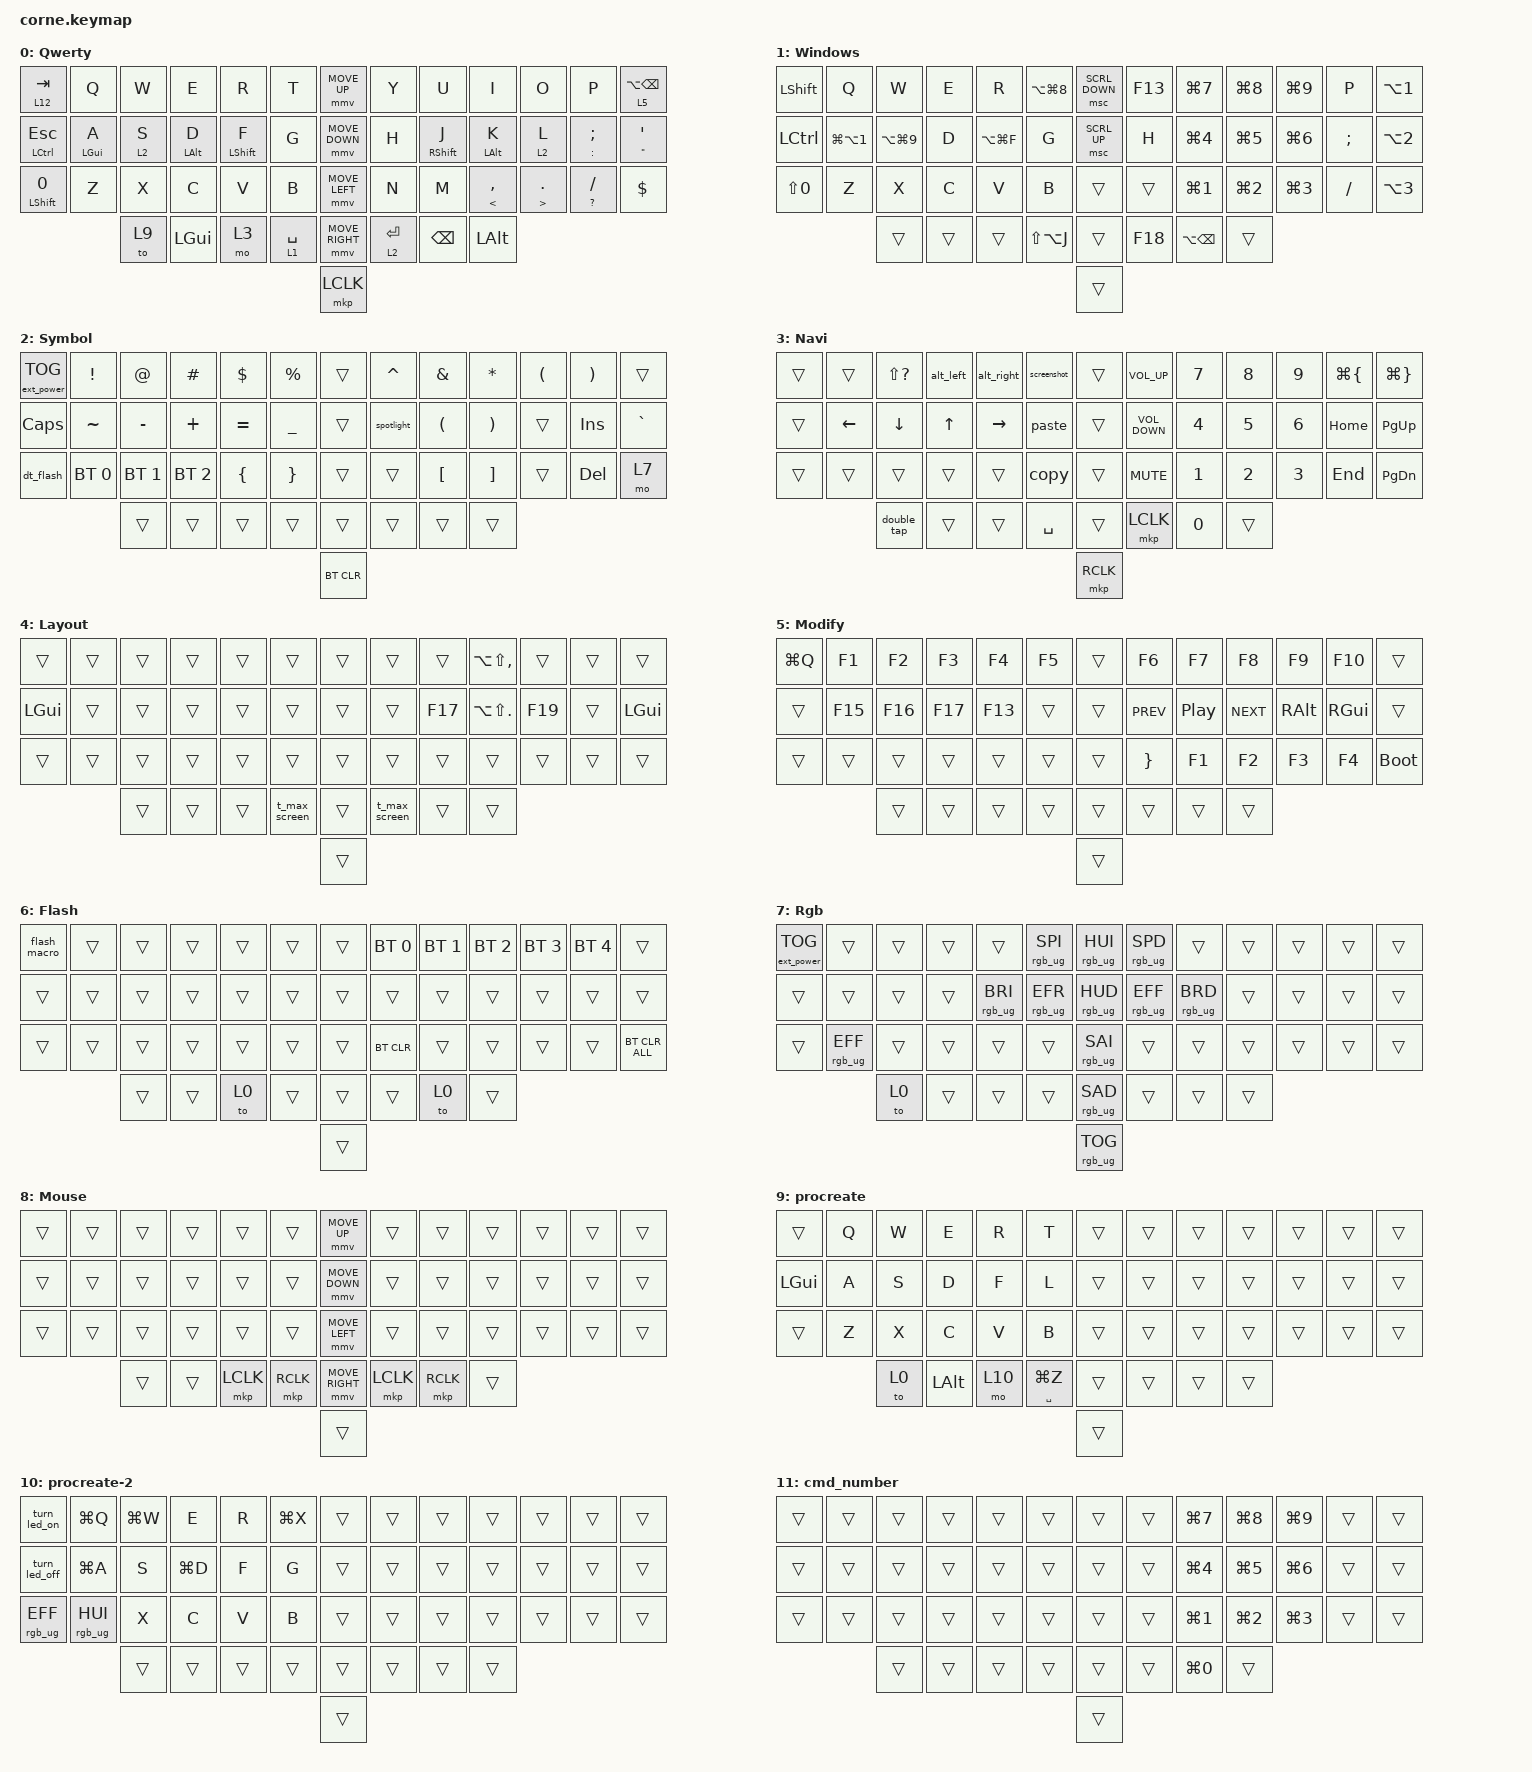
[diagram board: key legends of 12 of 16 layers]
#define ZMK_POINTING_DEFAULT_MOVE_VAL 1200  // 600
#define ZMK_POINTING_DEFAULT_SCRL_VAL 35    // 10

#include <input/processors.dtsi>
#include <zephyr/dt-bindings/input/input-event-codes.h>
#include <behaviors.dtsi>
#include <dt-bindings/zmk/bt.h>
#include <dt-bindings/zmk/ext_power.h>
#include <dt-bindings/zmk/keys.h>
#include <dt-bindings/zmk/pointing.h>
#include <dt-bindings/zmk/rgb.h>

/ {
    zip_scroll_scaler: zip_scroll_scaler {
        compatible = "zmk,input-processor-scaler";
        #input-processor-cells = <2>;
        type = <INPUT_EV_REL>;
        codes = <INPUT_REL_WHEEL INPUT_REL_HWHEEL>;
        track-remainders;
    };
};

&mmv_input_listener { input-processors = <&zip_xy_scaler 2 1>; };

&msc_input_listener { input-processors = <&zip_scroll_scaler 2 1>; };

&msc {
    acceleration-exponent = <0>;      // 0
    time-to-max-speed-ms = <0>;       // 300
    delay-ms = <0>;                   // 0
};

&mmv {
    time-to-max-speed-ms = <400>;
    acceleration-exponent = <1>;
};

/ {
    macros {
        t_max_screen: toggle_max_screen {
            compatible = "zmk,behavior-macro";
            #binding-cells = <0>;
            bindings = <&kp LG(LS(SPACE))>;
            label = "TOGGLE_MAX_SCREEN";
        };

        vim_exit: vim_exit {
            compatible = "zmk,behavior-macro";
            #binding-cells = <0>;
            bindings = <&kp ESCAPE &kp LA(C) &kp COLON>;
            label = "VIM_EXIT";
        };

        screenshot: screenshot {
            compatible = "zmk,behavior-macro";
            #binding-cells = <0>;
            bindings = <&kp LG(LS(NUMBER_4))>;
            label = "SCREENSHOT";
        };

        spotlight: spotlight {
            compatible = "zmk,behavior-macro";
            #binding-cells = <0>;
            bindings = <&kp LG(SPACE)>;
            label = "SPOTLIGHT";
        };

        alt_left: alt_left {
            compatible = "zmk,behavior-macro";
            #binding-cells = <0>;
            bindings = <&kp LA(LEFT)>;
            label = "ALT_LEFT";
        };

        alt_right: alt_right {
            compatible = "zmk,behavior-macro";
            #binding-cells = <0>;
            bindings = <&kp LA(RIGHT)>;
            label = "ALT_RIGHT";
        };

        copy: copy {
            compatible = "zmk,behavior-macro";
            #binding-cells = <0>;
            bindings = <&kp LG(C)>;
            label = "COPY";
        };

        paste: paste {
            compatible = "zmk,behavior-macro";
            #binding-cells = <0>;
            bindings = <&kp LG(V)>;
            label = "PASTE";
        };

        ctrl_right: ctrl_right {
            compatible = "zmk,behavior-macro";
            #binding-cells = <0>;
            bindings = <&kp LC(RIGHT)>;
            label = "CTRL_RIGHT";
        };

        ctrl_left: ctrl_left {
            compatible = "zmk,behavior-macro";
            #binding-cells = <0>;
            bindings = <&kp LC(LEFT)>;
            label = "CTRL_LEFT";
        };

        focus_1_screen: focus_1_screen {
            compatible = "zmk,behavior-macro";
            #binding-cells = <0>;
            bindings = <&kp LS(LA(LC(W)))>;
            label = "FOCUS_1_SCREEN";
        };

        focus_2_screen: focus_2_screen {
            compatible = "zmk,behavior-macro";
            #binding-cells = <0>;
            bindings = <&kp LS(LA(LC(E)))>;
            label = "FOCUS_2_SCREEN";
        };

        focus_3_screen: focus_3_screen {
            compatible = "zmk,behavior-macro";
            #binding-cells = <0>;
            bindings = <&kp LS(LA(LC(R)))>;
            label = "FOCUS_3_SCREEN";
        };

        throw_1_screen: throw_1_screen {
            compatible = "zmk,behavior-macro";
            #binding-cells = <0>;
            bindings = <&kp LS(LA(LC(M)))>;
            label = "THROW_1_SCREEN";
        };

        throw_2_screen: throw_2_screen {
            compatible = "zmk,behavior-macro";
            #binding-cells = <0>;
            bindings = <&kp LS(LA(LC(E)))>;
            label = "THROW_2_SCREEN";
        };

        throw_3_screen: throw_3_screen {
            compatible = "zmk,behavior-macro";
            #binding-cells = <0>;
            bindings = <&kp LS(LA(LC(R)))>;
            label = "THROW_3_SCREEN";
        };

        throw_1_space: throw_1_space {
            compatible = "zmk,behavior-macro";
            #binding-cells = <0>;
            bindings = <&kp LS(LA(LC(LG(J))))>;
            label = "THROW_1_SPACE";
        };

        throw_2_space: throw_2_space {
            compatible = "zmk,behavior-macro";
            #binding-cells = <0>;
            bindings = <&kp LS(LA(LC(LG(K))))>;
            label = "THROW_2_SPACE";
        };

        throw_3_space: throw_3_space {
            compatible = "zmk,behavior-macro";
            #binding-cells = <0>;
            bindings = <&kp LS(LA(LC(LG(L))))>;
            label = "THROW_3_SPACE";
        };

        throw_4_space: throw_4_space {
            compatible = "zmk,behavior-macro";
            #binding-cells = <0>;
            bindings = <&kp LS(LA(LC(LG(U))))>;
            label = "THROW_4_SPACE";
        };

        throw_5_space: throw_5_space {
            compatible = "zmk,behavior-macro";
            #binding-cells = <0>;
            bindings = <&kp LS(LA(LC(LG(I))))>;
            label = "THROW_5_SPACE";
        };

        throw_6_space: throw_6_space {
            compatible = "zmk,behavior-macro";
            #binding-cells = <0>;
            bindings = <&kp LS(LC(LA(LG(O))))>;
            label = "THROW_6_SPACE";
        };

        focus_space_1: focus_space_1 {
            compatible = "zmk,behavior-macro";
            #binding-cells = <0>;
            bindings = <&kp LS(LA(LC(J)))>;
            label = "FOCUS_SPACE_1";
        };

        focus_space_2: focus_space_2 {
            compatible = "zmk,behavior-macro";
            #binding-cells = <0>;
            bindings = <&kp LS(LC(LA(K)))>;
            label = "FOCUS_SPACE_2";
        };

        focus_space_3: focus_space_3 {
            compatible = "zmk,behavior-macro";
            #binding-cells = <0>;
            bindings = <&kp LS(LA(LC(L)))>;
            label = "FOCUS_SPACE_3";
        };

        focus_space_4: focus_space_4 {
            compatible = "zmk,behavior-macro";
            #binding-cells = <0>;
            bindings = <&kp LS(LA(LC(U)))>;
            label = "FOCUS_SPACE_4";
        };

        focus_space_5: focus_space_5 {
            compatible = "zmk,behavior-macro";
            #binding-cells = <0>;
            bindings = <&kp LS(LA(LC(I)))>;
            label = "FOCUS_SPACE_5";
        };

        focus_space_6: focus_space_6 {
            compatible = "zmk,behavior-macro";
            #binding-cells = <0>;
            bindings = <&kp LS(LA(LC(O)))>;
            label = "FOCUS_SPACE_6";
        };

        attach_windows: attatch_windows {
            compatible = "zmk,behavior-macro";
            #binding-cells = <0>;
            bindings = <&bt BT_SEL 3 &to 1>;
            label = "ATTATCH_WINDOWS";
        };

        attach_mac_personal: attach_mac_personal {
            compatible = "zmk,behavior-macro";
            #binding-cells = <0>;
            bindings = <&bt BT_SEL 0 &to 0>;
            label = "ATTACH_MAC_PERSONAL";
        };

        attach_mac_work: attach_mac_work {
            compatible = "zmk,behavior-macro";
            #binding-cells = <0>;
            bindings = <&bt BT_SEL 1 &to 0>;
            label = "ATTACH_MAC_WORK";
        };

        flash_macro: flash_macro {
            compatible = "zmk,behavior-macro";
            #binding-cells = <0>;
            bindings = <&bootloader>;
        };

        turn_led_on: turn_led_on {
            compatible = "zmk,behavior-macro";
            #binding-cells = <0>;
            bindings = <&ext_power EP_ON &rgb_ug RGB_ON>;
            label = "TURN_LED_ON";
        };

        turn_led_off: turn_led_off {
            compatible = "zmk,behavior-macro";
            #binding-cells = <0>;
            bindings = <&ext_power EP_OFF>;
            label = "TURN_LED_OFF";
        };

        vim_ciw: vim_ciw {
            compatible = "zmk,behavior-macro";
            #binding-cells = <0>;
            bindings = <&kp C &kp I &kp W>;
            label = "VIM_CIW";
        };
    };

    behaviors {
        hml: homerow_mods_left {
            compatible = "zmk,behavior-hold-tap";
            label = "HOMEROW_MODS_LEFT";
            bindings = <&kp>, <&kp>;

            #binding-cells = <2>;
            tapping-term-ms = <200>;
            quick-tap-ms = <180>;
            flavor = "tap-preferred";
            require-prior-idle-ms = <200>;
            hold-trigger-key-positions = <21 22 23 24>;
            hold-trigger-on-release;
            hold-while-undecided;
        };

        ltq: ltq {
            compatible = "zmk,behavior-hold-tap";
            label = "LTQ";
            bindings = <&mo>, <&kp>;

            #binding-cells = <2>;
            tapping-term-ms = <250>;
            quick-tap-ms = <150>;
            flavor = "tap-preferred";
        };

        as: auto_shift {
            compatible = "zmk,behavior-hold-tap";
            label = "AUTO_SHIFT";
            bindings = <&kp>, <&kp>;

            #binding-cells = <2>;
            tapping-term-ms = <180>;
            quick-tap-ms = <0>;
            flavor = "tap-preferred";
        };

        rgb_encoder: rgb_encoder {
            compatible = "zmk,behavior-sensor-rotate";
            label = "RGB_ENCODER";
            #sensor-binding-cells = <0>;
            bindings = <&rgb_ug RGB_BRI>, <&rgb_ug RGB_BRD>;
        };

        scroll_encoder: scroll_encoder {
            compatible = "zmk,behavior-sensor-rotate";
            #sensor-binding-cells = <0>;
            bindings = <&msc SCRL_UP>, <&msc SCRL_DOWN>;

            tap-ms = <30>;
        };

        hmr: hmr {
            compatible = "zmk,behavior-hold-tap";
            label = "HMR";
            bindings = <&kp>, <&kp>;

            #binding-cells = <2>;
            tapping-term-ms = <200>;
            quick-tap-ms = <180>;
            flavor = "tap-preferred";
            require-prior-idle-ms = <200>;
            hold-trigger-key-positions = <17 16 15 14>;
            hold-trigger-on-release;
            hold-while-undecided;
        };

        long_hold: long_hold {
            compatible = "zmk,behavior-hold-tap";
            label = "LONG_HOLD";
            bindings = <&none>, <&none>;

            #binding-cells = <2>;
            tapping-term-ms = <1000>;
            flavor = "tap-preferred";
        };

        double_tap: double_tap {
            compatible = "zmk,behavior-tap-dance";
            label = "DOUBLE_TAP";
            #binding-cells = <0>;
            bindings = <&bt BT_CLR>;
            tapping-term-ms = <200>;
        };

        dt_flash: dt_flash {
            compatible = "zmk,behavior-tap-dance";
            label = "DT_FLASH";
            #binding-cells = <0>;
            bindings = <&none>, <&to 6>;
        };

        hml_layer: hml_layer {
            compatible = "zmk,behavior-hold-tap";
            label = "HML_LAYER";
            bindings = <&mo>, <&kp>;

            #binding-cells = <2>;
            hold-trigger-key-positions = <15 23>;
            tapping-term-ms = <200>;
            quick-tap-ms = <180>;
            require-prior-idle-ms = <(-1)>;
            flavor = "tap-preferred";
        };

        quick_tap: quick_tap {
            compatible = "zmk,behavior-hold-tap";
            label = "QUICK_TAP";
            bindings = <&kp>, <&kp>;

            #binding-cells = <2>;
            tapping-term-ms = <180>;
            quick-tap-ms = <0>;
            require-prior-idle-ms = <0>;
            hold-trigger-on-release;
            hold-while-undecided;
        };
    };

    combos {
        compatible = "zmk,combos";

        combo_right_esc {
            bindings = <&mo 4>;
            key-positions = <46 38>;
            timeout-ms = <70>;
        };

        combo_left_esc {
            bindings = <&mo 4>;
            key-positions = <26 40>;
            timeout-ms = <70>;
        };

        combo_vim {
            bindings = <&vim_exit>;
            key-positions = <41 45>;
            timeout-ms = <150>;
        };

        quick_tap_esc {
            bindings = <&kp ESC>;
            key-positions = <26 40>;
            timeout-ms = <20>;
        };

        l4 {
            bindings = <&to 6>;
            key-positions = <46 40>;
        };

        backslash {
            bindings = <&kp BACKSLASH>;
            key-positions = <7 21>;
            timeout-ms = <100>;
        };

        comma {
            bindings = <&kp COMMA>;
            key-positions = <18 20>;
        };

        lock_pc {
            bindings = <&kp LG(LC(Q))>;
            key-positions = <0 42 44 12>;
            timeout-ms = <150>;
        };

        pipe {
            bindings = <&kp PIPE>;
            key-positions = <20 7>;
        };

        ctrl-c {
            bindings = <&kp LC(C)>;
            key-positions = <13 25>;
        };

        flash {
            bindings = <&to 6>;
            key-positions = <47 39>;
        };

        period_combo {
            bindings = <&kp PERIOD>;
            key-positions = <21 17>;
        };

        enter-left-hand {
            bindings = <&kp ENTER>;
            key-positions = <14 15 16 17>;
        };

        ciw {
            bindings = <&vim_ciw>;
            key-positions = <25 13>;
        };

        esc_thumb {
            bindings = <&kp ESCAPE>;
            key-positions = <42 44>;
        };

        move_window {
            bindings = <&mo 15>;
            key-positions = <46 12>;
        };

        delete {
            bindings = <&kp LA(DELETE)>;
            key-positions = <15 17>;
        };
    };

    keymap {
        compatible = "zmk,keymap";

        Qwerty {
            bindings = <
&lt 12 TAB                &kp Q            &kp W           &kp E            &kp R              &kp T           &mmv MOVE_UP     &kp Y         &kp U               &kp I                &kp O                    &kp P               &lt 5 LA(BACKSPACE)
&mt LEFT_CONTROL ESC      &hml LEFT_GUI A  &hml_layer 2 S  &hml LEFT_ALT D  &hml LEFT_SHIFT F  &kp G           &mmv MOVE_DOWN   &kp H         &hmr RIGHT_SHIFT J  &hmr LEFT_ALT K      &hml_layer 2 L           &as COLON SEMI      &as DOUBLE_QUOTES SQT
&quick_tap LEFT_SHIFT N0  &kp Z            &kp X           &kp C            &kp V              &kp B           &mmv MOVE_LEFT   &kp N         &kp M               &as LESS_THAN COMMA  &as GREATER_THAN PERIOD  &as QUESTION SLASH  &kp DOLLAR
                                           &to 9           &kp LEFT_GUI     &mo 3              &ltq 1 SPACE    &mmv MOVE_RIGHT  &ltq 2 ENTER  &kp BACKSPACE       &kp LEFT_ALT
                                                                                                               &mkp LCLK
            >;

            label = "Qwerty";
            sensor-bindings = <&inc_dec_kp C_VOLUME_UP C_VOLUME_DOWN>;
        };

        Windows {
            bindings = <
&kp LEFT_SHIFT  &kp Q                 &kp W           &kp E   &kp R          &kp LA(LG(N8))    &msc SCRL_DOWN  &kp F13  &kp LG(N7)         &kp LG(N8)        &kp LG(N9)        &kp P     &kp LA(NUMBER_1)
&kp LCTRL       &kp LG(LA(NUMBER_1))  &kp LA(LG(N9))  &kp D   &kp LA(LG(F))  &kp G             &msc SCRL_UP    &kp H    &kp LG(NUMBER_4)   &kp LG(N5)        &kp LG(NUMBER_6)  &kp SEMI  &kp LA(NUMBER_2)
&kp LS(N0)      &kp Z                 &kp X           &kp C   &kp V          &kp B             &trans          &trans   &kp LG(NUMBER_1)   &kp LG(NUMBER_2)  &kp LG(NUMBER_3)  &kp FSLH  &kp LA(NUMBER_3)
                                      &trans          &trans  &trans         &kp LS(LA(J))     &trans          &kp F18  &kp LA(BACKSPACE)  &trans
                                                                                               &trans
            >;
        };

        Symbol {
            bindings = <
&ext_power EP_TOG  &kp EXCLAMATION  &kp AT_SIGN   &kp HASH      &kp DOLLAR      &kp PERCENT        &trans      &kp CARET   &kp AMPERSAND         &kp ASTERISK           &kp LEFT_PARENTHESIS  &kp RIGHT_PARENTHESIS  &trans
&kp CAPSLOCK       &kp TILDE        &kp MINUS     &kp PLUS      &kp EQUAL       &kp UNDERSCORE     &trans      &spotlight  &kp LEFT_PARENTHESIS  &kp RIGHT_PARENTHESIS  &trans                &kp INSERT             &kp GRAVE
&dt_flash          &bt BT_SEL 0     &bt BT_SEL 1  &bt BT_SEL 2  &kp LEFT_BRACE  &kp RIGHT_BRACE    &trans      &trans      &kp LEFT_BRACKET      &kp RIGHT_BRACKET      &trans                &kp DELETE             &mo 7
                                    &trans        &trans        &trans          &trans             &trans      &trans      &trans                &trans
                                                                                                   &bt BT_CLR
            >;

            label = "Symbol";
        };

        Navi {
            bindings = <
&trans  &trans    &kp LS(QMARK)  &alt_left  &alt_right  &screenshot    &trans     &kp C_VOLUME_UP    &kp N7  &kp N8  &kp N9  &kp LG(LEFT_BRACE)  &kp LG(RIGHT_BRACE)
&trans  &kp LEFT  &kp DOWN       &kp UP     &kp RIGHT   &paste         &trans     &kp C_VOLUME_DOWN  &kp N4  &kp N5  &kp N6  &kp HOME            &kp PAGE_UP
&trans  &trans    &trans         &trans     &trans      &copy          &trans     &kp K_MUTE         &kp N1  &kp N2  &kp N3  &kp END             &kp PAGE_DOWN
                  &double_tap    &trans     &trans      &kp SPACE      &trans     &mkp LCLK          &kp N0  &trans
                                                                       &mkp RCLK
            >;

            sensor-bindings = <&inc_dec_kp RIGHT_ARROW LEFT_ARROW>;
            label = "Navi";
        };

        Layout {
            bindings = <
&trans        &trans  &trans  &trans  &trans  &trans           &trans  &trans         &trans   &kp LA(LS(COMMA))   &trans   &trans  &trans
&kp LEFT_GUI  &trans  &trans  &trans  &trans  &trans           &trans  &trans         &kp F17  &kp LA(LS(PERIOD))  &kp F19  &trans  &kp LEFT_GUI
&trans        &trans  &trans  &trans  &trans  &trans           &trans  &trans         &trans   &trans              &trans   &trans  &trans
                      &trans  &trans  &trans  &t_max_screen    &trans  &t_max_screen  &trans   &trans
                                                               &trans
            >;
        };

        Modify {
            bindings = <
&kp LG(Q)  &kp F1   &kp F2   &kp F3   &kp F4   &kp F5    &trans  &kp F6           &kp F7    &kp F8      &kp F9         &kp F10        &trans
&trans     &kp F15  &kp F16  &kp F17  &kp F13  &trans    &trans  &kp C_PREV       &kp C_PP  &kp C_NEXT  &kp RIGHT_ALT  &kp RIGHT_GUI  &trans
&trans     &trans   &trans   &trans   &trans   &trans    &trans  &kp RIGHT_BRACE  &kp F1    &kp F2      &kp F3         &kp F4         &bootloader
                    &trans   &trans   &trans   &trans    &trans  &trans           &trans    &trans
                                                         &trans
            >;

            label = "Modify";
        };

        Flash {
            bindings = <
&flash_macro  &trans  &trans  &trans  &trans  &trans    &trans  &bt BT_SEL 0  &bt BT_SEL 1  &bt BT_SEL 2  &bt BT_SEL 3  &bt BT_SEL 4  &trans
&trans        &trans  &trans  &trans  &trans  &trans    &trans  &trans        &trans        &trans        &trans        &trans        &trans
&trans        &trans  &trans  &trans  &trans  &trans    &trans  &bt BT_CLR    &trans        &trans        &trans        &trans        &bt BT_CLR_ALL
                      &trans  &trans  &to 0   &trans    &trans  &trans        &to 0         &trans
                                                        &trans
            >;

            label = "Flash";
        };

        Rgb {
            bindings = <
&ext_power EP_TOG  &trans           &trans  &trans  &trans           &rgb_ug RGB_SPI    &rgb_ug RGB_HUI  &rgb_ug RGB_SPD  &trans           &trans  &trans  &trans  &trans
&trans             &trans           &trans  &trans  &rgb_ug RGB_BRI  &rgb_ug RGB_EFR    &rgb_ug RGB_HUD  &rgb_ug RGB_EFF  &rgb_ug RGB_BRD  &trans  &trans  &trans  &trans
&trans             &rgb_ug RGB_EFF  &trans  &trans  &trans           &trans             &rgb_ug RGB_SAI  &trans           &trans           &trans  &trans  &trans  &trans
                                    &to 0   &trans  &trans           &trans             &rgb_ug RGB_SAD  &trans           &trans           &trans
                                                                                        &rgb_ug RGB_TOG
            >;

            label = "Rgb";
            sensor-bindings = <&rgb_encoder &scroll_encoder>;
        };

        Mouse {
            bindings = <
&trans  &trans  &trans  &trans  &trans     &trans       &mmv MOVE_UP     &trans     &trans     &trans  &trans  &trans  &trans
&trans  &trans  &trans  &trans  &trans     &trans       &mmv MOVE_DOWN   &trans     &trans     &trans  &trans  &trans  &trans
&trans  &trans  &trans  &trans  &trans     &trans       &mmv MOVE_LEFT   &trans     &trans     &trans  &trans  &trans  &trans
                &trans  &trans  &mkp LCLK  &mkp RCLK    &mmv MOVE_RIGHT  &mkp LCLK  &mkp RCLK  &trans
                                                        &trans
            >;

            label = "Mouse";
            sensor-bindings = <&scroll_encoder>;
        };

        procreate {
            bindings = <
&trans        &kp Q  &kp W  &kp E         &kp R   &kp T              &trans  &trans  &trans  &trans  &trans  &trans  &trans
&kp LEFT_GUI  &kp A  &kp S  &kp D         &kp F   &kp L              &trans  &trans  &trans  &trans  &trans  &trans  &trans
&trans        &kp Z  &kp X  &kp C         &kp V   &kp B              &trans  &trans  &trans  &trans  &trans  &trans  &trans
                     &to 0  &kp LEFT_ALT  &mo 10  &mt SPACE LG(Z)    &trans  &trans  &trans  &trans
                                                                     &trans
            >;

            sensor-bindings = <&inc_dec_kp LG(RIGHT_BRACKET) LG(LEFT_BRACKET)>;
        };

        procreate-2 {
            bindings = <
&turn_led_on     &kp LG(Q)        &kp LG(W)  &kp E      &kp R   &kp LG(X)    &trans  &trans  &trans  &trans  &trans  &trans  &trans
&turn_led_off    &kp LG(A)        &kp S      &kp LG(D)  &kp F   &kp G        &trans  &trans  &trans  &trans  &trans  &trans  &trans
&rgb_ug RGB_EFF  &rgb_ug RGB_HUI  &kp X      &kp C      &kp V   &kp B        &trans  &trans  &trans  &trans  &trans  &trans  &trans
                                  &trans     &trans     &trans  &trans       &trans  &trans  &trans  &trans
                                                                             &trans
            >;
        };

        cmd_number {
            bindings = <
&trans  &trans  &trans  &trans  &trans  &trans    &trans  &trans  &kp LG(N7)        &kp LG(N8)  &kp LG(N9)  &trans  &trans
&trans  &trans  &trans  &trans  &trans  &trans    &trans  &trans  &kp LG(N4)        &kp LG(N5)  &kp LG(N6)  &trans  &trans
&trans  &trans  &trans  &trans  &trans  &trans    &trans  &trans  &kp LG(NUMBER_1)  &kp LG(N2)  &kp LG(N3)  &trans  &trans
                &trans  &trans  &trans  &trans    &trans  &trans  &kp LG(N0)        &trans
                                                  &trans
            >;
        };

        cmd-shift-number {
            bindings = <
&trans  &trans  &trans  &trans  &trans  &trans    &trans  &trans  &kp LG(N7)            &kp LG(N8)      &kp LG(N9)      &trans  &trans
&trans  &trans  &trans  &trans  &trans  &trans    &trans  &trans  &kp LG(LS(N4))        &kp LG(N5)      &kp LG(N6)      &trans  &trans
&trans  &trans  &trans  &trans  &trans  &trans    &trans  &trans  &kp LG(LS(NUMBER_1))  &kp LG(LS(N2))  &kp LG(LS(N3))  &trans  &trans
                &trans  &trans  &trans  &mo 14    &trans  &trans  &kp LA(BACKSPACE)     &trans
                                                  &trans
            >;
        };

        ctrl_number {
            bindings = <
&trans  &trans  &trans  &trans  &trans  &trans    &trans  &trans  &kp LC(N7)  &kp LC(N8)  &kp LC(N9)  &trans      &trans
&trans  &trans  &trans  &trans  &trans  &trans    &trans  &trans  &kp LC(N4)  &kp LC(N5)  &kp LC(N6)  &trans      &trans
&trans  &trans  &trans  &trans  &trans  &trans    &trans  &trans  &kp LC(N1)  &kp LC(N2)  &kp LC(N3)  &bt BT_PRV  &bt BT_NXT
                &trans  &trans  &trans  &trans    &trans  &trans  &kp LC(N0)  &trans
                                                  &trans
            >;
        };

        alt-number {
            bindings = <
&trans  &trans  &trans  &trans  &trans  &trans        &trans  &trans  &kp LC(N7)  &kp LC(N8)  &kp LC(N9)  &trans  &trans
&trans  &trans  &trans  &trans  &trans  &trans        &trans  &trans  &kp LA(N4)  &kp LC(N5)  &kp LC(N6)  &trans  &trans
&trans  &trans  &trans  &trans  &trans  &trans        &trans  &trans  &kp F17     &kp F18     &kp F19     &trans  &trans
                &trans  &trans  &trans  &kp LSHIFT    &trans  &trans  &kp LC(N0)  &trans
                                                      &trans
            >;
        };

        move_window {
            bindings = <
&trans  &trans  &trans             &kp LA(LC(BACKSLASH))  &trans             &trans              &trans  &trans  &trans  &trans  &trans  &trans  &trans
&trans  &trans  &kp LA(LC(COMMA))  &kp LC(LA(PERIOD))     &kp LA(LC(SLASH))  &trans              &trans  &trans  &trans  &trans  &trans  &trans  &trans
&trans  &trans  &trans             &trans                 &trans             &trans              &trans  &trans  &trans  &trans  &trans  &trans  &trans
                &trans             &trans                 &trans             &kp LA(LC(HASH))    &trans  &trans  &trans  &trans
                                                                                                 &trans
            >;
        };
    };

    conditional_layers {
        compatible = "zmk,conditional-layers";

        Flash {
            if-layers = <5 2>;
            then-layer = <6>;
        };
    };
};
